# STM32WBA25 register map
File version: 1.0
CPU: CM33 r0p1, little endian, MPU, FPU, 4 interrupt priority bits
Registers are 32-bit, read-write, reset 0x0 unless marked. A register's access mark holds for its fields unless they carry their own. Offsets are from the block's base; [hi:lo] are bit positions.

## GTZC1_TZIC — GTZC1_TZIC address block description
Base 0x40032800
Same registers: SEC_GTZC1_TZIC 0x50032800
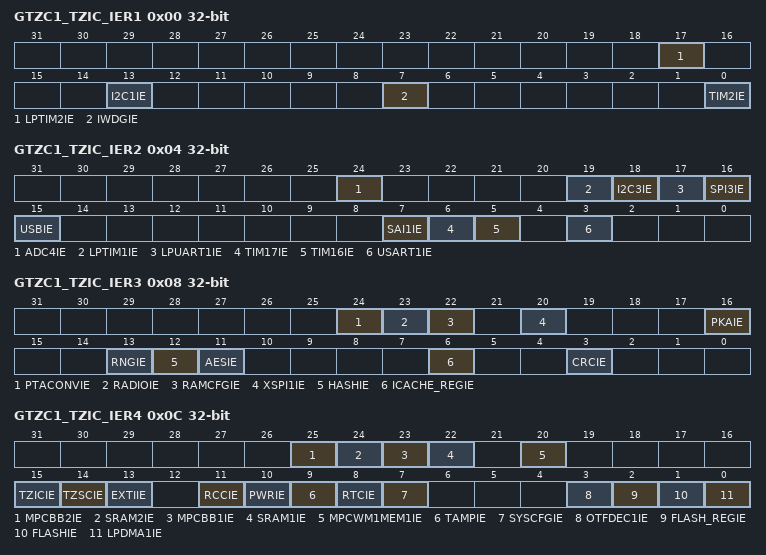
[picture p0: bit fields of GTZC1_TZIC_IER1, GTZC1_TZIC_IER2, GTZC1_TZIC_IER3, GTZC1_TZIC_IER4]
0x00 GTZC1_TZIC_IER1 (alternate view of GTZC1_TZSC_CR) — GTZC1 TZIC interrupt enable register 1
  [all] fields
    0=Interrupt disabled; 1=Interrupt enabled
  [17] LPTIM2IE — Illegal access interrupt enable for LPTIM2
  [13] I2C1IE — Illegal access interrupt enable for I2C1
  [7] IWDGIE — Illegal access interrupt enable for IWDG
  [0] TIM2IE — Illegal access interrupt enable for TIM2
0x04 GTZC1_TZIC_IER2 — GTZC1 TZIC interrupt enable register 2
  [all] fields
    0=Interrupt disabled; 1=Interrupt enabled
  [24] ADC4IE — Illegal access interrupt enable for ADC4
  [19] LPTIM1IE — Illegal access interrupt enable for LPTIM1
  [18] I2C3IE — Illegal access interrupt enable for I2C3
  [17] LPUART1IE — Illegal access interrupt enable for LPUART1
  [16] SPI3IE — Illegal access interrupt enable for SPI3
  [15] USBIE — Illegal access interrupt enable for USB
  [7] SAI1IE — Illegal access interrupt enable for SAI1
  [6] TIM17IE — Illegal access interrupt enable for TIM17
  [5] TIM16IE — Illegal access interrupt enable for TIM16
  [3] USART1IE — Illegal access interrupt enable for USART1
0x08 GTZC1_TZIC_IER3 — GTZC1 TZIC interrupt enable register 3
  [all] fields
    0=Interrupt disabled; 1=Interrupt enabled
  [24] PTACONVIE — Illegal access interrupt enable for PTACONV
  [23] RADIOIE — Illegal access interrupt enable for 2.
  [22] RAMCFGIE — Illegal access interrupt enable for RAMCFG
  [20] XSPI1IE — Illegal access interrupt enable for XSPI1
  [16] PKAIE — Illegal access interrupt enable for PKA
  [13] RNGIE — Illegal access interrupt enable for RNG
  [12] HASHIE — Illegal access interrupt enable for HASH
  [11] AESIE — Illegal access interrupt enable for AES
  [6] ICACHE_REGIE — Illegal access interrupt enable for ICACHE registers
  [3] CRCIE — Illegal access interrupt enable for CRC
0x0C GTZC1_TZIC_IER4 — GTZC1 TZIC interrupt enable register 4
  [25] MPCBB2IE — Illegal access interrupt enable for MPCBB2
    0=Interrupt disabled; 1=Interrupt enabled
  [24] SRAM2IE — Illegal access interrupt enable for SRAM2
    0=Interrupt disabled; 1=Interrupt enabled
  [23] MPCBB1IE — Illegal access interrupt enable for MPCBB1
    0=Interrupt disabled; 1=Interrupt enabled
  [22] SRAM1IE — Illegal access interrupt enable for SRAM1
    0=Interrupt disabled; 1=Interrupt enabled
  [20] MPCWM1MEM1IE
  [15] TZICIE — Illegal access interrupt enable for GTZC1 TZIC
    0=Interrupt disabled; 1=Interrupt enabled
  [14] TZSCIE — Illegal access interrupt enable for GTZC1 TZSC
    0=Interrupt disabled; 1=Interrupt enabled
  [13] EXTIIE — Illegal access interrupt enable for EXTI
    0=Interrupt disabled; 1=Interrupt enabled
  [11] RCCIE — Illegal access interrupt enable for RCC
    0=Interrupt disabled; 1=Interrupt enabled
  [10] PWRIE — Illegal access interrupt enable for PWR
    0=Interrupt disabled; 1=Interrupt enabled
  [9] TAMPIE — Illegal access interrupt enable for TAMP
    0=Interrupt disabled; 1=Interrupt enabled
  [8] RTCIE — Illegal access interrupt enable for RTC
    0=Interrupt disabled; 1=Interrupt enabled
  [7] SYSCFGIE — Illegal access interrupt enable for SYSCFG
    0=Interrupt disabled; 1=Interrupt enabled
  [3] OTFDEC1IE — Illegal access interrupt enable for OTFDEC1
    0=Interrupt disabled; 1=Interrupt enabled
  [2] FLASH_REGIE — Illegal access interrupt enable for FLASH interface
    0=Interrupt disabled; 1=Interrupt enabled
  [1] FLASHIE — Illegal access interrupt enable for FLASH memory
    0=Interrupt disabled; 1=Interrupt enabled
  [0] LPDMA1IE — Illegal access interrupt enable for LPDMA1
    0=Interrupt disabled; 1=Interrupt enabled
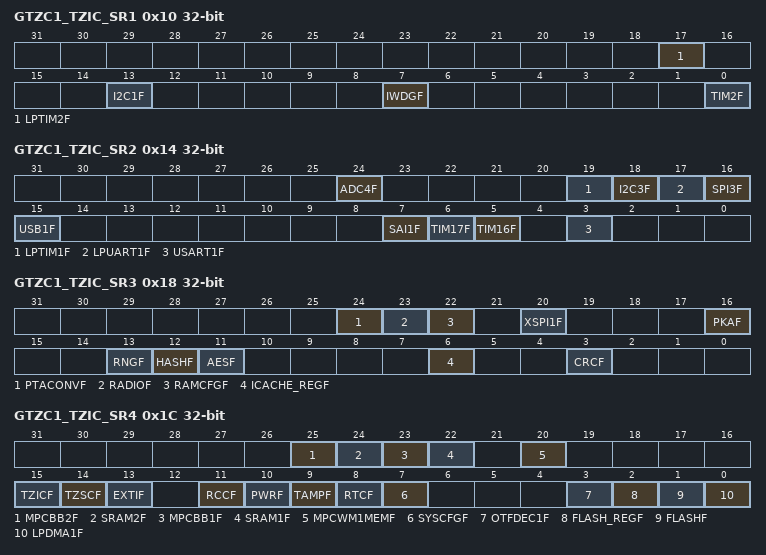
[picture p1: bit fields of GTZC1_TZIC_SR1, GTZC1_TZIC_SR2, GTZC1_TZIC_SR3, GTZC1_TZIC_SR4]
0x10 GTZC1_TZIC_SR1 ro (alternate view of GTZC1_TZSC_SECCFGR1) — GTZC1 TZIC status register 1
  [all] fields
    0=No illegal access event; 1=Illegal access event
  [17] LPTIM2F — Illegal access flag for LPTIM2
  [13] I2C1F — Illegal access flag for I2C1
  [7] IWDGF — Illegal access flag for IWDG
  [0] TIM2F — Illegal access flag for TIM2
0x14 GTZC1_TZIC_SR2 ro (alternate view of GTZC1_TZSC_SECCFGR2) — GTZC1 TZIC status register 2
  [24] ADC4F — Illegal access flag for ADC4
    0=No illegal access event; 1=Illegal access event
  [19] LPTIM1F — Illegal access flag for LPTIM1
    0=No illegal access event; 1=Illegal access event
  [18] I2C3F — Illegal access flag for I2C3
    0=No illegal access event; 1=Illegal access event
  [17] LPUART1F — Illegal access flag for LPUART1
    0=No illegal access event; 1=Illegal access event
  [16] SPI3F — Illegal access flag for SPI3
    0=No illegal access event; 1=Illegal access event
  [15] USB1F
  [7] SAI1F — Illegal access flag for SAI1
    0=No illegal access event; 1=Illegal access event
  [6] TIM17F — Illegal access flag for TIM17
    0=No illegal access event; 1=Illegal access event
  [5] TIM16F — Illegal access flag for TIM16
    0=No illegal access event; 1=Illegal access event
  [3] USART1F — Illegal access flag for USART1
    0=No illegal access event; 1=Illegal access event
0x18 GTZC1_TZIC_SR3 ro (alternate view of GTZC1_TZSC_SECCFGR3) — GTZC1 TZIC status register 3
  [all] fields
    0=No illegal access event; 1=Illegal access event
  [24] PTACONVF — Illegal access flag for PTACONV
  [23] RADIOF — Illegal access flag for 2.
  [22] RAMCFGF — Illegal access flag for RAMCFG
  [20] XSPI1F — Illegal access flag for XSPI1
  [16] PKAF — Illegal access flag for PKA
  [13] RNGF — Illegal access flag for RNG
  [12] HASHF — Illegal access flag for HASH
  [11] AESF — Illegal access flag for AES
  [6] ICACHE_REGF — Illegal access flag for ICACHE registers
  [3] CRCF — Illegal access flag for CRC
0x1C GTZC1_TZIC_SR4 ro — GTZC1 TZIC status register 4
  [all] fields
    0=No illegal access event; 1=Illegal access event
  [25] MPCBB2F — Illegal access flag for MPCBB2
  [24] SRAM2F — Illegal access flag for SRAM2
  [23] MPCBB1F — Illegal access flag for MPCBB1
  [22] SRAM1F — Illegal access flag for SRAM1
  [20] MPCWM1MEMF — Illegal access flag for MPCWM1 protected external memory
  [15] TZICF — Illegal access flag for GTZC1 TZIC
  [14] TZSCF — Illegal access flag for GTZC1 TZSC
  [13] EXTIF — Illegal access flag for EXTI
  [11] RCCF — Illegal access flag for RCC
  [10] PWRF — Illegal access flag for PWR
  [9] TAMPF — Illegal access flag for TAMP
  [8] RTCF — Illegal access flag for RTC
  [7] SYSCFGF — Illegal access flag for SYSCFG
  [3] OTFDEC1F — Illegal access flag for OTFDEC1
  [2] FLASH_REGF — Illegal access flag for FLASH interface
  [1] FLASHF — Illegal access flag for FLASH memory
  [0] LPDMA1F — Illegal access flag for LPDMA1
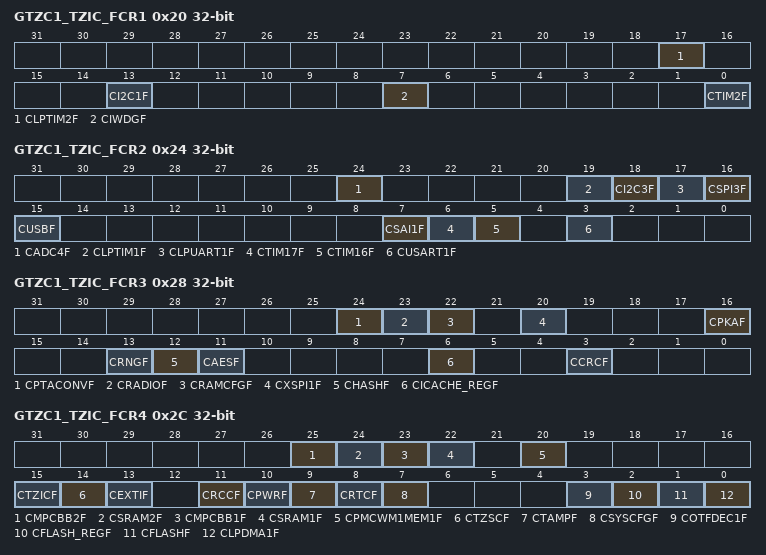
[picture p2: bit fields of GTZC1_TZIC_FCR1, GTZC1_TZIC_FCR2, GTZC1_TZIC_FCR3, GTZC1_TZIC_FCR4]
0x20 GTZC1_TZIC_FCR1 wo (alternate view of GTZC1_TZSC_PRIVCFGR1) — GTZC1 TZIC flag clear register 1
  [all] fields
    0=No action; 1=Status flag cleared
  [17] CLPTIM2F — Clear the illegal access flag for LPTIM2
  [13] CI2C1F — Clear the illegal access flag for I2C1
  [7] CIWDGF — Clear the illegal access flag for IWDG
  [0] CTIM2F — Clear the illegal access flag for TIM2
0x24 GTZC1_TZIC_FCR2 wo (alternate view of GTZC1_TZSC_PRIVCFGR2) — GTZC1 TZIC flag clear register 2
  [all] fields
    0=No action; 1=Status flag cleared
  [24] CADC4F — Clear the illegal access flag for ADC4
  [19] CLPTIM1F — Clear the illegal access flag for LPTIM1
  [18] CI2C3F — Clear the illegal access flag for I2C3
  [17] CLPUART1F — Clear the illegal access flag for LPUART1
  [16] CSPI3F — Clear the illegal access flag for SPI3
  [15] CUSBF — Clear the illegal access flag for USB
  [7] CSAI1F — Clear the illegal access flag for SAI1
  [6] CTIM17F — Clear the illegal access flag for TIM17
  [5] CTIM16F — Clear the illegal access flag for TIM16
  [3] CUSART1F — Clear the illegal access flag for USART1
0x28 GTZC1_TZIC_FCR3 wo (alternate view of GTZC1_TZSC_PRIVCFGR3) — GTZC1 TZIC flag clear register 3
  [all] fields
    0=No action; 1=Status flag cleared
  [24] CPTACONVF — Clear the illegal access flag for PTACONV
  [23] CRADIOF — Clear the illegal access flag for 2.
  [22] CRAMCFGF — Clear the illegal access flag for RAMCFG
  [20] CXSPI1F — Clear the illegal access flag for XSPI1
  [16] CPKAF — Clear the illegal access flag for PKA
  [13] CRNGF — Clear the illegal access flag for RNG
  [12] CHASHF — Clear the illegal access flag for HASH
  [11] CAESF — Clear the illegal access flag for AES
  [6] CICACHE_REGF — Clear the illegal access flag for ICACHE registers
  [3] CCRCF — Clear the illegal access flag for CRC
0x2C GTZC1_TZIC_FCR4 wo — GTZC1 TZIC flag clear register 4
  [25] CMPCBB2F — Clear the illegal access flag for MPCBB2
    0=No action; 1=Status flag cleared
  [24] CSRAM2F — Clear the illegal access flag for SRAM2
    0=No action; 1=Status flag cleared
  [23] CMPCBB1F — Clear the illegal access flag for MPCBB1
    0=No action; 1=Status flag cleared
  [22] CSRAM1F — Clear the illegal access flag for SRAM1
    0=No action; 1=Status flag cleared
  [20] CPMCWM1MEM1F
  [15] CTZICF — Clear the illegal access flag for GTZC1 TZIC
    0=No action; 1=Status flag cleared
  [14] CTZSCF — Clear the illegal access flag for GTZC1 TZSC
    0=No action; 1=Status flag cleared
  [13] CEXTIF — Clear the illegal access flag for EXTI
    0=No action; 1=Status flag cleared
  [11] CRCCF — Clear the illegal access flag for RCC
    0=No action; 1=Status flag cleared
  [10] CPWRF — Clear the illegal access flag for PWR
    0=No action; 1=Status flag cleared
  [9] CTAMPF — Clear the illegal access flag for TAMP
    0=No action; 1=Status flag cleared
  [8] CRTCF — Clear the illegal access flag for RTC
    0=No action; 1=Status flag cleared
  [7] CSYSCFGF — Clear the illegal access flag for SYSCFG
    0=No action; 1=Status flag cleared
  [3] COTFDEC1F
  [2] CFLASH_REGF — Clear the illegal access flag for FLASH interface
    0=No action; 1=Status flag cleared
  [1] CFLASHF — Clear the illegal access flag for FLASH memory
    0=No action; 1=Status flag cleared
  [0] CLPDMA1F — Clear the illegal access flag for LPDMA1
    0=No action; 1=Status flag cleared
